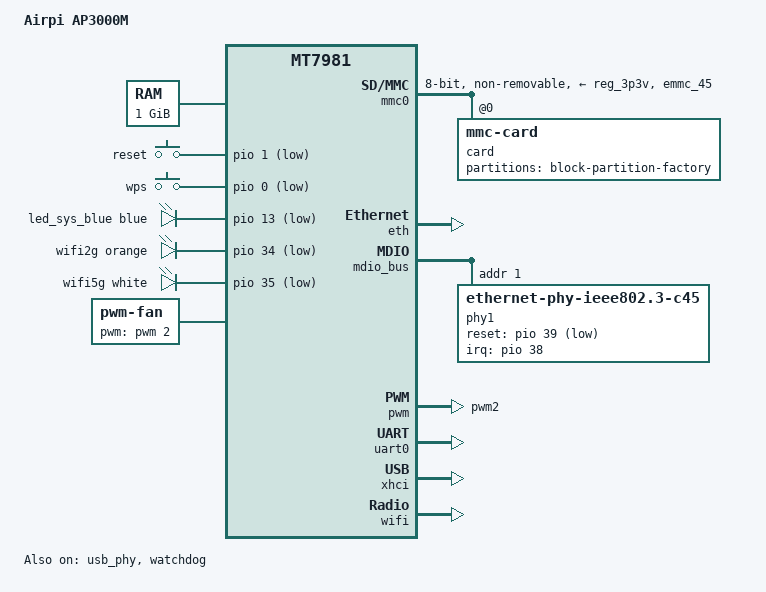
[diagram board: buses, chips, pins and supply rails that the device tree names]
// SPDX-License-Identifier: (GPL-2.0 OR MIT)

/dts-v1/;

#include <dt-bindings/gpio/gpio.h>
#include <dt-bindings/input/input.h>
#include <dt-bindings/leds/common.h>

#include "mt7981b.dtsi"

/ {
	model = "Airpi AP3000M";
	compatible = "airpi,ap3000m", "mediatek,mt7981";

	aliases {
		ethernet0 = &gmac0;
		ethernet1 = &gmac1;
		serial0 = &uart0;

		led-boot = &led_sys_blue;
		led-failsafe = &led_sys_blue;
		led-running = &led_sys_blue;
		led-upgrade = &led_sys_blue;
	};

	chosen {
		stdout-path = "serial0:115200n8";
		bootargs = "root=PARTLABEL=rootfs rootwait";
	};

	memory {
		reg = <0 0x40000000 0 0x40000000>;
	};


	gpio-keys {
		compatible = "gpio-keys";

		reset {
			label = "reset";
			linux,code = <KEY_RESTART>;
			gpios = <&pio 1 GPIO_ACTIVE_LOW>;
		};

		wps {
			label = "wps";
			linux,code = <KEY_WPS_BUTTON>;
			gpios = <&pio 0 GPIO_ACTIVE_LOW>;
		};
	};

	gpio-leds {
		compatible = "gpio-leds";

		led_sys_blue: led-0 {
			function = LED_FUNCTION_STATUS;
			color = <LED_COLOR_ID_BLUE>;
			gpios = <&pio 13 GPIO_ACTIVE_LOW>;
		};

		wifi2g: led-1 {
			function = LED_FUNCTION_WLAN_2GHZ;
			color = <LED_COLOR_ID_ORANGE>;
			gpios = <&pio 34 GPIO_ACTIVE_LOW>;
			linux,default-trigger = "phy0tpt";
		};

		wifi5g: led-2 {
			function = LED_FUNCTION_WLAN_5GHZ;
			color = <LED_COLOR_ID_WHITE>;
			gpios = <&pio 35 GPIO_ACTIVE_LOW>;
			linux,default-trigger = "phy1tpt";
		};
	};

	fan: pwm-fan {
		compatible = "pwm-fan";
		#cooling-cells = <2>;
		cooling-levels = <0 10 20 30 40 50 60 70 80 90 100 110 120 130 140 150 160 170 180 190 200 210 220 240 255>;
		pwms = <&pwm 2 40000 0>;
		status = "okay";
	};

};

&mmc0 {
	pinctrl-names = "default", "state_uhs";
	pinctrl-0 = <&mmc0_pins_default>;
	pinctrl-1 = <&mmc0_pins_uhs>;
	bus-width = <8>;
	max-frequency = <52000000>;
	vmmc-supply = <&reg_3p3v>;
	cap-mmc-highspeed;
	no-sd;
	no-sdio;
	non-removable;
	status = "okay";
	
	card@0 {
		compatible = "mmc-card";
		reg = <0>;

		block {
			compatible = "block-device";

			partitions {
				block-partition-factory {
					partname = "factory";

					nvmem-layout {
						compatible = "fixed-layout";
						#address-cells = <1>;
						#size-cells = <1>;

						eeprom_factory_0: eeprom@0 {
							reg = <0x0 0x1000>;
						};
						
						macaddr_factory_24: macaddr@24 {
							compatible = "mac-base";
							reg = <0x24 0x6>;
							#nvmem-cell-cells = <1>;
						};

						macaddr_factory_2a: macaddr@2a {
							compatible = "mac-base";
							reg = <0x2a 0x6>;
							#nvmem-cell-cells = <1>;
						};
					};
				};
			};
		};
	};
};


&eth {
	pinctrl-names = "default";
	pinctrl-0 = <&mdio_pins>;
	status = "okay";

	gmac0: mac@0 {
		compatible = "mediatek,eth-mac";
		reg = <0>;
		phy-mode = "2500base-x";
		phy-handle = <&phy1>;
		nvmem-cells = <&macaddr_factory_24 0>;
		nvmem-cell-names = "mac-address";
	};

	gmac1: mac@1 {
		compatible = "mediatek,eth-mac";
		reg = <1>;
		phy-mode = "gmii";
		phy-handle = <&int_gbe_phy>;
		nvmem-cells = <&macaddr_factory_2a 0>;
		nvmem-cell-names = "mac-address";
	};
};

&mdio_bus {
	phy1: ethernet-phy@1 {
		compatible = "ethernet-phy-ieee802.3-c45";
		reg = <1>;
		reset-assert-us = <100000>;
		reset-deassert-us = <100000>;
		reset-gpios = <&pio 39 GPIO_ACTIVE_LOW>;
		interrupts = <38 IRQ_TYPE_LEVEL_LOW>;
		interrupt-parent = <&pio>;
		realtek,aldps-enable;
	};
};

&pio {
	mmc0_pins_default: mmc0-pins-default {
		mux {
			function = "flash";
			groups = "emmc_45";
		};
	};

	mmc0_pins_uhs: mmc0-pins-uhs {
		mux {
			function = "flash";
			groups = "emmc_45";
		};
	};

	pwm2_pins: pwm2-pins {
		mux {
			function = "pwm";
			groups = "pwm2";
		};
	};
};

&pwm {
	pinctrl-names = "default";
	pinctrl-0 = <&pwm2_pins>;
	status = "okay";
};

&uart0 {
	status = "okay";
};

&usb_phy {
	status = "okay";
};

&watchdog {
	status = "okay";
};

&xhci {
	status = "okay";
};

&wifi {
	mediatek,eeprom-data = <0x81790000 0x000c4326 0x60000000 0x00000000 0x00000000 0x00000000 0x00000000 0x00000000 0x00000000 0x00000000 0x00000000 0x00000000 0x00000000 0x00000000 0x00000000 0x00000000 0x00000000 0x00000000 0x00000000 0x00000000 0x00000000 0x00000000 0x00000000 0x00000000 0x00000000 0x00000000 0x00000000 0x00000000 0x00000000 0x00000000 0x00000000 0x00000000 0x00000000 0x00000000 0x00000000 0x00000000 0x00000000 0x00000000 0x00000000 0x00000000 0x00000000 0x00000000 0x00000000 0x00000000 0x00000000 0x00000000 0x00000000 0x00000000 0x00000000 0x00000000 0x00000000 0x00000000 0x00000000 0x00000000 0x00000000 0x00000000 0x00000000 0x00000000 0x00000000 0x00000000 0x00000000 0x00000000 0x00000000 0x00000000 0x00000000 0x00000000 0x00000000 0x00000000 0x00000000 0x00000000 0x00000000 0x00000000 0x00000000 0x00000000 0x00000000 0x00000000 0x00000000 0x00000000 0x00000000 0x00000000 0x00000000 0x00000000 0x00000000 0x00000000 0x00000000 0x00000000 0x00000000 0x00000000 0x00000000 0x00000000 0x00000000 0x00000000 0x00000000 0x00000000 0x00000000 0x00000000 0x00000000 0x00000000 0x00000000 0x00000000 0x125b484c 0x00280000 0x05d00000 0x00000000 0x00000000 0x00000000 0x00000000 0x00000000 0x00000000 0x00000000 0x00000000 0x00000000 0x00000000 0x00000000 0x00000000 0x00000000 0x00000000 0x00000000 0x00000000 0x00000000 0x00000000 0x00000000 0x00000000 0x00000000 0x00000000 0x00000000 0x00000000 0x00000000 0x00000000 0x00000000 0x00000000 0x00000000 0x00000000 0x00000000 0x00000000 0x00000000 0x00000000 0x00000000 0x00000000 0x00000000 0x00000000 0x00000000 0x00000000 0x00000000 0x00000000 0x00000000 0x00000000 0x00000000 0x00000000 0x00000000 0x00000000 0x00000000 0x00000000 0x00000000 0x00000000 0x00000000 0x00000000 0x00000000 0x00000000 0x00000000 0x00000000 0x00000000 0x00000000 0x00000000 0x00000000 0x00000000 0x00000000 0x00000000 0x00000000 0x00000000 0x00000000 0x00000000 0x00000000 0x00000000 0x00000000 0x00000000 0x00000000 0x00000000 0x00000000 0x00000000 0x00000000 0x00000000 0x00000000 0x00000000 0x00000000 0x00000000 0x00000000 0x00000000 0x00000000 0x00000000 0x00000000 0x00000000 0x00000000 0x00000000 0x00000000 0x00000000 0x00000000 0x00000000 0x00000000 0x00000000 0x00000000 0x00000000 0x00000000 0x00000000 0x00000000 0x00000000 0x00000000 0x00000000 0x00000000 0x00000000 0x00000000 0x00000000 0x00000000 0x00000000 0x00000000 0x00000000 0x00000000 0x00000000 0x00000000 0x00000000 0x00000000 0x00000000 0x00000000 0x00000000 0x00000000 0x00000000 0x00000000 0x00000000 0x00000000 0x00000000 0x00000000 0x00000000 0x00000000 0x00000000 0x00000000 0x00000000 0x00000000 0x00000000 0x00000000 0x00000000 0x00000000 0x00000000 0x00000000 0x00000000 0x00000000 0x00000000 0x00000000 0x00000000 0x00000000 0x00000012 0x12120000 0x00000000 0x00000000 0x00002222 0x22223333 0x33333333 0x33333333 0x33333333 0x33333333 0x33333333 0x33333333 0x33330000 0x00000000 0x00000000 0x00000000 0x00000000 0x00000000 0x00000000 0x00000000 0x00000000 0x00000000 0x00000000 0x00292929 0x29282828 0x28282828 0x28282828 0x28282828 0x28282828 0x28000000 0x00000000 0x00000000 0x00242424 0x24222222 0x22242424 0x24222222 0x22242424 0x24222222 0x22242424 0x24222222 0x22000000 0x00000000 0x00000000 0x00000000 0x00000000 0x00000000 0x00000000 0x00000000 0x00000000 0x00000000 0x00000000 0x00000000 0x00000000 0x00000000 0x00000000 0x00000000 0x00000000 0x00000000 0x00000000 0x00000000 0x00000000 0x00000000 0x00000000 0x00000000 0x00000000 0x00000000 0x00000000 0x00000000 0x00000000 0x00000000 0x00000000 0x00000000 0x00000000 0x00000000 0x00000000 0x00000000 0x00000000 0x00000000 0x00000000 0x00000000 0x00000000 0x00000000 0x00000000 0x00000000 0x00000000 0x00000000 0x00000000 0x00000000 0x00000000 0x00000000 0x00000000 0x00000000 0x00000000 0x00000000 0x00000000 0x00000000 0x00000000 0x00000000 0x00000000 0x00000000 0x00000000 0x00000000 0x00000000 0x00000000 0x007f7f7f 0xd1d1dddd 0xe9e9f5f5 0x01010909 0x1515d1d1 0xdddde9e9 0xf5f5fdfd 0x09091515 0xd1d1dddd 0xe9e9f5f5 0xfdfd0909 0x1515d1d1 0xdddde9e9 0xf5f5fdfd 0x09091515 0x00000000 0x00000000 0x00000000 0x00000000 0x00000000 0x00000000 0x00000000 0x00000000 0x00000000 0x00000000 0x00000000 0x00000000 0x00000000 0x00000000 0x00000000 0x00000000 0x1cf2fc00 0x00000000 0x00000000 0x00000000 0x00000000 0x00000000 0x00000000 0x00000000 0x00000000 0x00000000 0x00000000 0x00000000 0x00000000 0x00000000 0x00000000 0x00000000 0x00000000 0x00000000 0x00000000 0x00000000 0x00000000 0x00000000 0x00000000 0x00000000 0x00000000 0x00000000 0x00000000 0x00000000 0x00000000 0x00000000 0x00000000 0x00000000 0x00000000 0x00000000 0x00000000 0x00000000 0x00000000 0x00000000 0x00000000 0x00000000 0x00000000 0x00000000 0x00000000 0x00000000 0x00000000 0x00000000 0x00000000 0x00000000 0x00000000 0x00000000 0x00000000 0x00000000 0x00000000 0x00000000 0x00000000 0x00000000 0x00000000 0x00000000 0x00000000 0x00000000 0x00000000 0x00000000 0x00000000 0x00000000 0x00000000 0x00000000 0x00000000 0x00000000 0x00000000 0x00000000 0x00000000 0x00000000 0x00000000 0x00000000 0x00000000 0x00000000 0x00000000 0x00000000 0x00000000 0x00000000 0x00000000 0x00000000 0x00000000 0x00000000 0x00000000 0x00000000 0x00000000 0x00000000 0x00000000 0x00000000 0x00000000 0x00000000 0x00000000 0x00000000 0x00000000 0x00000000 0x00000000 0x00000000 0x00000000 0x00000000 0x021e021e 0x02000200 0x02370237 0x02370237 0x02370237 0x02370237 0x02370237 0x02370237 0x02370237 0x02370237 0x02370237 0x02370237 0x02370237 0x02370237 0x02370237 0x02370237 0x002200c6 0xc6c4c4c3 0x0000c1c2 0xc1838383 0x838686c1 0xc1838383 0x838686c2 0xc1c18181 0x82838585 0x8686c1c1 0x81818283 0x85858686 0xc1c18181 0x82838585 0x8686c1c1 0x81818283 0x85858686 0xc1c18181 0x82838585 0x8686c5c5 0xc3c100c2 0xc3c2c200 0x81828383 0xc2c2c200 0x81828383 0xc3c1c1c1 0x81828384 0x84c2c2c2 0xc2008182 0x83838585 0xc2c2c200 0x81828383 0x8585c1c1 0xc1818283 0x84848686 0x82828484 0x85868787 0x8989c2c2 0xc2008182 0x83838585 0xc2c2c200 0x81828383 0x8585c2c2 0xc2008182 0x83838585 0xc4c4c2c1 0x00c3c3c3 0xc1008183 0x838686c3 0xc3c3c100 0x81838386 0x86c2c2c2 0x00818284 0x84868682 0x82828485 0x8688888b 0x8bc3c3c3 0xc1008183 0x838686c3 0xc3c3c100 0x81838386 0x86c3c3c3 0xc1008183 0x83868600 0x00000000 0x00000000 0x00000000 0x00000000 0x00000000 0x00000000 0x00000000 0x00000000 0x00000000 0x00000000 0x00000000 0x00000000 0x00000000 0x00000000 0x00000000 0x00000000 0x00000000 0x00000000 0x00000000 0x00000000 0x00000000 0x00000000 0x00000000 0x00000000 0x00000000 0x00000000 0x00000000 0x00000000 0x00000000 0x00000000 0x00000000 0x00000000 0x00000000 0x00000000 0x00000000 0x00000000 0x00000000 0x00000000 0x00000000 0x00000000 0x00000000 0x00000000 0x00000000 0x00000000 0x00000000 0x00000000 0x00000000 0x00000000 0x00bd0000 0x00000000 0x00000000 0x00000000 0x00000000 0x00000000 0x00c50000 0x00000000 0x00000000 0x00000000 0x00000000 0x00000000 0x00000000 0x00000000 0x00000000 0x00000000 0x00000000 0x00000000 0x00000000 0x00000000 0x00000000 0x00000000 0x00000000 0x00000000 0x00000000 0x00000000 0x00000000 0x00000000 0x00000000 0x00000000 0x00000000 0x00000000 0x00000000 0x00000000 0x00000000 0x00000000 0x00495256 0x55555555 0x004a5251 0x51515151 0x004a5355 0x56565656 0x0049504e 0x51515151 0x00495150 0x54545454 0x00495051 0x51515151 0x00495251 0x50505050 0x00495251 0x51515151 0x00495251 0x54545454 0x00495150 0x54545454 0x00495352 0x51515151 0x00495353 0x52525252 0x00495150 0x50505050 0x00495152 0x54545454 0x00495251 0x53535353 0x00000000 0x00000000 0x00000000 0x00000000 0x00000000 0x00000000 0x00000000 0x00000000 0x00000000 0x00000000 0x00000000 0x00000000 0x00000000 0x00000000 0x00000000 0x00000000 0x00000000 0x00000000 0x00000000 0x00000000 0x00000000 0x00000000 0x00000000 0x00000000 0x00000000 0x00000000 0x00000000 0x00000000 0x00000000 0x00000000 0xd1d1dddd 0xe9e9f5f5 0xfdfd1414 0x1d1d0000 0x00000000 0x00000000 0x00000000 0x00000000 0x00000000 0x00000000 0x00000000 0x00000000 0x00000000 0x00000000 0x00000000 0x00000000 0x00000000 0x00000000 0x00000000 0x00000000 0x00000000 0x00000000 0x00000000 0x00000000 0x00000000 0x00000000 0x00000000 0x00000000 0x00000000 0x00000000 0x00000000 0x00000000 0x00000000 0x00000000 0x00000000 0x00000000 0x00000000 0x00000000 0x00000000 0x00000000 0x00000000 0x00000000 0x00000000 0x00000000 0x00000000 0x00000000 0x00000000 0x00000000 0x00000000 0x00000000 0x00000000 0x00000000 0x00000000 0x00000000 0x00000000 0x00000000 0x00000000 0x00000000 0x00000000 0x00000000 0x00000000 0x00000000 0x00000000 0x00000000 0x00000000 0x00000000 0x00000000 0x00000000 0x00000000 0x00000000 0x00000000 0x00000000 0x00000000 0x00000000 0x00000000 0x00000000 0x00000000 0x00000000 0x00000000 0x00000000 0x00000000 0x00000000 0x00000000 0x00000000 0x00000000 0x00000000 0x00000000 0x00000000 0x00000000 0x00000000 0x00000000 0x00000000 0x00000000 0x00000000 0x00000000 0x00000000 0x00000000 0x00000000 0x00000000 0x00000000 0x83840000 0xc3c4c382 0x828281c1 0xc4c5c400 0x0000c1c3 0xc4c4c481 0x8181c1c2 0x00000000 0x00000000 0x00000000 0x00000000 0x00000000 0x00000000 0x00000000 0x00000000 0x00000000 0x00000000 0x00000000 0x00000000 0x00000000 0x00000000 0x00000000 0x00000000 0x00000000 0xc0bbc0bb 0xc0bbc0bb 0x40c5c0c4 0xc0c3c0c3 0x40c340c5 0x40c4c0c3 0x40c3c0c2 0xc0c5c0c4 0x40c440c4 0xc0c3c0c5 0xc0c440c4 0x40c4c0c3 0x00000000 0x00000000 0x00000000 0x00000000 0x00000000 0x00000000 0x40c640c6 0x40c640c6 0x40c640c6 0x40c640c6 0x40c640c6 0x40c640c6 0x40c640c6 0x40c640c6 0x40c640c6 0x40c640c6 0x40c640c6 0x40c640c6 0x40c640c6 0x40c640c6 0x40c640c6 0x40c640c6 0x00000000 0x00000000 0x00000000 0x00000000 0x00000000 0x00000000 0x00000000 0x00000000 0x00000000 0x00000000 0x00000000 0x00000000 0x00000000 0x00000000 0x00000000 0x00000000 0x00000000 0x00000000 0x00000000 0x00000000 0x00000000 0x00000000 0x00000000 0x00000000 0x00000000 0x00000000 0x00000000 0x00000000 0x00000000 0x00000000 0x00000000 0x00000000 0x00000000 0x00000000 0x00000000 0x00000000 0x00000000 0x00000000 0x00000000 0x00000000 0x00000000 0x00000000 0x00000000 0x00000000 0x00000000 0x00000000 0x00000000 0x00000000 0x00000000 0x00000000 0x00000000 0x00000000 0x00000000 0x00000000 0x00000000 0x00000000 0x00000000 0x00000000 0x00000000 0x00000000 0x00000000 0x00000000 0x00000000 0x00000000 0x00000000 0x00000000 0x00000000 0x00000000 0x00000000 0x00000000 0x00000000 0x00000000 0x00000000 0x00000000 0x00000000 0x00000000 0x00000000 0x00000000 0x00000000 0x00000000 0x00000000 0x00000000 0x00000000 0x00000000 0x00000000 0x00000000 0x00000000 0x00000000 0x00000000 0x00000000 0x00000000 0x00000000 0x00000000 0x00000000 0x00000000 0x00000000 0x00000000 0x00000000 0x00000000 0x00000000 0x00000000 0x00000000 0x00000000 0x00000000 0x00000000 0x00000000 0x00000000 0x00000000 0x00000000 0x00000000 0x00000000 0x00000000 0x00000000 0x00000000 0x00000000 0x00000000 0x00000000 0x00000000 0x00000000 0x00000000 0x00000000 0x00000000 0x00000000 0x00000000 0x00000000 0x00000000 0x00000000 0x00000000 0x00000000 0x00000000 0x00000000 0x00000000 0x00000000 0x00000000 0x00000000 0x00000000 0x00000000 0x00000000 0x00000000 0x00000000 0x00000000 0x00000000 0x00000000 0x00000000 0x00000000 0x00000000 0x00000000 0x00000000 0x00000000 0x00000000 0x00000000 0x00000000 0x00000000 0x00000000 0x00000000 0x00000000 0x00000000 0x00000000>;
	status = "okay";
};
